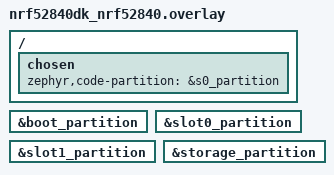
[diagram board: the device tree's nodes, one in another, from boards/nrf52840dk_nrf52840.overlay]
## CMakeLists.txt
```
#
# Copyright (c) 2018 Nordic Semiconductor ASA
#
# SPDX-License-Identifier: LicenseRef-BSD-5-Clause-Nordic
#

cmake_minimum_required(VERSION 3.8.2)

find_package(Zephyr REQUIRED HINTS $ENV{ZEPHYR_BASE})
project(NONE)

FILE(GLOB app_sources src/*.c)
target_sources(app PRIVATE ${app_sources})
```

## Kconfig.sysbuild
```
#
# Copyright (c) 2026 Nordic Semiconductor
#
# SPDX-License-Identifier: LicenseRef-Nordic-5-Clause
#

if SOC_SERIES_NRF54L

config SECURE_BOOT_GENERATE_DEFAULT_KMU_KEYFILE
	default y if SECURE_BOOT_APPCORE

endif

source "share/sysbuild/Kconfig"
```

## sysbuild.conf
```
#
# Copyright (c) 2024 Nordic Semiconductor
#
# SPDX-License-Identifier: LicenseRef-Nordic-5-Clause
#

SB_CONFIG_SECURE_BOOT_APPCORE=y
SB_CONFIG_SECURE_BOOT_DEBUG_SIGNATURE_PUBLIC_KEY_LAST=y
SB_CONFIG_SECURE_BOOT_PUBLIC_KEY_FILES="debug"
```

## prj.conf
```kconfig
#
# Copyright (c) 2018-2023 Nordic Semiconductor ASA
#
# SPDX-License-Identifier: LicenseRef-Nordic-5-Clause
#

CONFIG_ZTEST=y
CONFIG_ZTEST_STACK_SIZE=6144
CONFIG_SECURE_BOOT=y
CONFIG_FW_INFO=y
CONFIG_SECURE_BOOT_CRYPTO=y
CONFIG_SECURE_BOOT_VALIDATION=y
CONFIG_SECURE_BOOT_STORAGE=y
CONFIG_BL_VALIDATE_FW_EXT_API_REQUIRED=y
CONFIG_FLASH_MAP=y
CONFIG_MPU_ALLOW_FLASH_WRITE=y
CONFIG_NULL_POINTER_EXCEPTION_DETECTION_NONE=y
```

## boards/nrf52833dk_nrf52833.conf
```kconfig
CONFIG_SB_CRYPTO_OBERON_SHA256=y
CONFIG_NRFX_NVMC=y
```

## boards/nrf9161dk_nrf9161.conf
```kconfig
CONFIG_SB_CRYPTO_OBERON_SHA256=y
CONFIG_NRFX_NVMC=y
```

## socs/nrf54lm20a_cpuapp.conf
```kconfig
# Copyright (c) 2026 Nordic Semiconductor ASA
#
# SPDX-License-Identifier: LicenseRef-Nordic-5-Clause
#
CONFIG_SB_CRYPTO_NONE=y
CONFIG_SB_CRYPTO_PSA_ED25519=y
CONFIG_PSA_CRYPTO=y
CONFIG_NRFX_RRAMC=y
CONFIG_PSA_USE_CRACEN_AEAD_DRIVER=n
CONFIG_PSA_USE_CRACEN_MAC_DRIVER=n
CONFIG_PSA_USE_CRACEN_HASH_DRIVER=y
CONFIG_PSA_USE_CRACEN_CIPHER_DRIVER=y
CONFIG_PSA_USE_CRACEN_ASYMMETRIC_SIGNATURE_DRIVER=y

# NSIB blocks the KMU slots holding its signature keys before it boots this
# image, so signatures cannot be verified from the application. Requesting the
# BL_VALIDATE_FW EXT_API would abort a boot, because  NSIB does not export
# the API on this SoC series.
CONFIG_BL_VALIDATE_FW_EXT_API_UNUSED=y
```

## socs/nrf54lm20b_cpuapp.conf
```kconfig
# Copyright (c) 2026 Nordic Semiconductor ASA
#
# SPDX-License-Identifier: LicenseRef-Nordic-5-Clause
#
CONFIG_SB_CRYPTO_NONE=y
CONFIG_SB_CRYPTO_PSA_ED25519=y
CONFIG_PSA_CRYPTO=y
CONFIG_NRFX_RRAMC=y
CONFIG_PSA_USE_CRACEN_AEAD_DRIVER=n
CONFIG_PSA_USE_CRACEN_MAC_DRIVER=n
CONFIG_PSA_USE_CRACEN_HASH_DRIVER=y
CONFIG_PSA_USE_CRACEN_CIPHER_DRIVER=y
CONFIG_PSA_USE_CRACEN_ASYMMETRIC_SIGNATURE_DRIVER=y

# NSIB blocks the KMU slots holding its signature keys before it boots this
# image, so signatures cannot be verified from the application. Requesting the
# BL_VALIDATE_FW EXT_API would  abort a boot, because  NSIB does not export
# the API on this SoC series.
CONFIG_BL_VALIDATE_FW_EXT_API_UNUSED=y
```

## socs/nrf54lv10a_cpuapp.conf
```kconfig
# Copyright (c) 2026 Nordic Semiconductor ASA
#
# SPDX-License-Identifier: LicenseRef-Nordic-5-Clause
#
CONFIG_SB_CRYPTO_NONE=y
CONFIG_SB_CRYPTO_PSA_ED25519=y
CONFIG_PSA_CRYPTO=y
# CONFIG_NRFX_NVMC is not set
CONFIG_NRFX_RRAMC=y
CONFIG_PSA_USE_CRACEN_AEAD_DRIVER=n
CONFIG_PSA_USE_CRACEN_MAC_DRIVER=n
CONFIG_PSA_USE_CRACEN_HASH_DRIVER=y
CONFIG_PSA_USE_CRACEN_CIPHER_DRIVER=y
CONFIG_PSA_USE_CRACEN_ASYMMETRIC_SIGNATURE_DRIVER=y
```

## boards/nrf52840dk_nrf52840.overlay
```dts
/*
 * Copyright (c) 2026 Nordic Semiconductor ASA
 *
 * SPDX-License-Identifier: LicenseRef-Nordic-5-Clause
 */

b0_partition: &boot_partition {};

s0_partition: &slot0_partition {};

s1_partition: &slot1_partition {};

bl_storage: &storage_partition {};

/ {
	chosen {
		zephyr,code-partition = &s0_partition;
	};
};
```

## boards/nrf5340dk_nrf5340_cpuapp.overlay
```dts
/*
 * Copyright (c) 2026 Nordic Semiconductor ASA
 *
 * SPDX-License-Identifier: LicenseRef-Nordic-5-Clause
 */

b0_partition: &boot_partition {};

s0_partition: &slot0_partition {};

s1_partition: &slot1_partition {};

/ {
	chosen {
		zephyr,code-partition = &s0_partition;
	};
};
```

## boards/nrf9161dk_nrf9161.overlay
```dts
/*
 * Copyright (c) 2026 Nordic Semiconductor ASA
 *
 * SPDX-License-Identifier: LicenseRef-Nordic-5-Clause
 */

b0_partition: &boot_partition {};

s0_partition: &slot0_partition {};

s1_partition: &slot1_partition {};
```

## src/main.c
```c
/*
 * Copyright (c) 2018 Nordic Semiconductor ASA
 *
 * SPDX-License-Identifier: LicenseRef-Nordic-5-Clause
 */

#include <zephyr/ztest.h>
#include <bl_validation.h>
#include <fw_info.h>
#include <zephyr/sys/util.h>
#include <zephyr/linker/linker-defs.h>
#include <zephyr/devicetree.h>
#include <zephyr/storage/flash_map.h>

#if defined(CONFIG_NRFX_RRAMC)
#include <nrfx_rramc.h>
#define PROTECTION_BLOCK_SIZE 0x800
#else
#include <nrfx_nvmc.h>
#define PROTECTION_BLOCK_SIZE 0x8000
#endif

#define S0_SLOT_ADDRESS		PARTITION_ADDRESS(s0_partition)
#define S1_SLOT_ADDRESS		PARTITION_ADDRESS(s1_partition)

ZTEST(bl_validation_test, test_key_looping)
{
	/* If this boots, the test passed. The public key is at the end of the
	 * list, so the bootloader looped through all to validate this app.
	 */
}

#if defined(CONFIG_SOC_SERIES_NRF54L)

/* On the nRF54L series the bootloader blocks the KMU slots holding its
 * signature keys before booting this image, so firmware signatures can no
 * longer be verified from the application. The test cases are still defined
 * here because Twister builds its expected test case list by scanning this
 * file, and a case that never reports a result is counted as a failure.
 */
ZTEST(bl_validation_test, test_validation)
{
	ztest_test_skip();
}

ZTEST(bl_validation_test, test_s1)
{
	ztest_test_skip();
}

#else

/* 1. Validate current app in place. Expect success.
 * 2. Validate current app without first 0x200 bytes. Expect failure.
 * 3. Validate current app copied to somewhere else. Expect success.
 * 4. Validate copy against wrong address. Expect failure.
 * 5. Validate mangled copy. Expect failure
 */
ZTEST(bl_validation_test, test_validation)
{
	zassert_true(bl_validate_firmware(S0_SLOT_ADDRESS, S0_SLOT_ADDRESS),
		"Fail 1. Failed to validate current app.\r\n");
	zassert_false(bl_validate_firmware(S0_SLOT_ADDRESS, S0_SLOT_ADDRESS + 0x200),
		"Fail 2. Incorrectly validated app with wrong offset.\r\n");

	/* 0x1000 to account for validation info. */
	uint32_t copy_len = (uint32_t)_flash_used + 1000;

	/* Round up to at least the next protection region. */
	uint32_t new_addr = ROUND_UP(S0_SLOT_ADDRESS + copy_len, PROTECTION_BLOCK_SIZE);

#if defined(CONFIG_SOC_SERIES_NRF54L)
	nrfx_rramc_write_enable_set(true, 0);
	nrfx_rramc_words_write(new_addr, (const uint32_t *)S0_SLOT_ADDRESS,
		(copy_len + 3) / 4);
#else
	for (uint32_t erase_addr = new_addr; erase_addr < (new_addr + copy_len);
	     erase_addr += DT_PROP(DT_CHOSEN(zephyr_flash), erase_block_size)) {
		int ret = nrfx_nvmc_page_erase(erase_addr);

		zassert_equal(0, ret, "Erase failed.\r\n");
	}
	nrfx_nvmc_words_write(new_addr, (const uint32_t *)S0_SLOT_ADDRESS,
		(copy_len + 3) / 4);
#endif

	zassert_true(bl_validate_firmware(S0_SLOT_ADDRESS, new_addr),
		"Fail 3. Failed to validate displaced app.\r\n");

	zassert_false(bl_validate_firmware(S0_SLOT_ADDRESS + 0x300, new_addr),
		"Fail 4. Incorrectly validated copy against wrong addr.\r\n");

	uint32_t mangle_addr = new_addr + 0x300;

	zassert_not_equal(0, *(uint32_t *)mangle_addr,
		"Unable to mangle, word is 0. \r\n");

#if defined(CONFIG_SOC_SERIES_NRF54L)
	nrfx_rramc_word_write(mangle_addr, 0);
#else
	nrfx_nvmc_word_write(mangle_addr, 0);
#endif

	zassert_equal(0, *(uint32_t *)mangle_addr,
		"Unable to mangle, word was not written to 0. \r\n");

	zassert_false(bl_validate_firmware(S0_SLOT_ADDRESS, new_addr),
		"Fail 5. Incorrectly validated mangled app.\r\n");
}


ZTEST(bl_validation_test, test_s1)
{
	/* Sanity check to confirm whether build system generated s1
	 * image properly validates after flashing to the slot it is supposed
	 * to boot from.
	 */
	zassert_true(bl_validate_firmware(S1_SLOT_ADDRESS, S1_SLOT_ADDRESS), NULL);
}

#endif /* CONFIG_SOC_SERIES_NRF54L */

ZTEST_SUITE(bl_validation_test, NULL, NULL, NULL, NULL, NULL);
```
